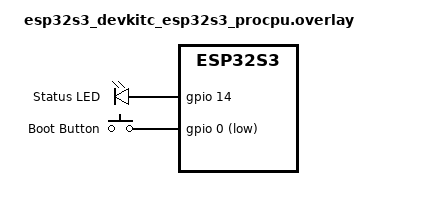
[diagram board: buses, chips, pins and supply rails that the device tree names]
/ {
    /* LED and button for the ESP32-S3 DevKitC. */
    leds {
        compatible = "gpio-leds";
        led0: led_0 {
            gpios = <&gpio 14 GPIO_ACTIVE_HIGH>; /* External LED */
            label = "Status LED";
        };
    };

    buttons {
        compatible = "gpio-keys";
        button0: button_0 {
            gpios = <&gpio 0 (GPIO_PULL_UP | GPIO_ACTIVE_LOW)>; /* Onboard BOOT button */
            label = "Boot Button";
        };
    };

    aliases {
        led0 = &led0;
        sw0 = &button0;
    };
};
